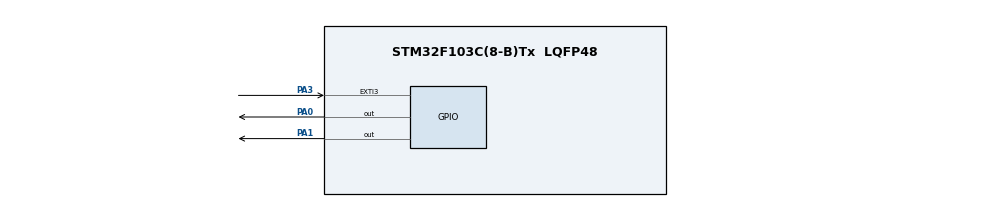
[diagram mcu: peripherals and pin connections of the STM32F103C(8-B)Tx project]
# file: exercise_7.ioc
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Mcu.Family=STM32F1
Mcu.Name=STM32F103C(8-B)Tx
Mcu.Package=LQFP48
NVIC.EXTI3_IRQn=true\:5\:0\:true\:false\:true\:true\:true\:true
NVIC.PriorityGroup=NVIC_PRIORITYGROUP_4
NVIC.TIM2_IRQn=true\:15\:0\:false\:false\:true\:false\:true\:true
NVIC.TimeBase=TIM2_IRQn
NVIC.TimeBaseIP=TIM2
PA0-WKUP.Signal=GPIO_Output
PA1.Signal=GPIO_Output
PA13.Mode=Serial_Wire
PA13.Signal=SYS_JTMS-SWDIO
PA14.Mode=Serial_Wire
PA14.Signal=SYS_JTCK-SWCLK
PA3.Signal=GPXTI3
ProjectManager.HeapSize=0x200
ProjectManager.StackSize=0x400
ProjectManager.TargetToolchain=STM32CubeIDE
RCC.APB1Freq_Value=8000000
RCC.APB2Freq_Value=8000000
VP_SYS_VS_tim2.Mode=TIM2
board=custom

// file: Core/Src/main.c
/* USER CODE BEGIN Header */
/**
  ******************************************************************************
  * @file           : main.c
  * @brief          : Main program body
  ******************************************************************************
  * @attention
  *
  * Copyright (c) 2024 STMicroelectronics.
  * All rights reserved.
  *
  * This software is licensed under terms that can be found in the LICENSE file
  * in the root directory of this software component.
  * If no LICENSE file comes with this software, it is provided AS-IS.
  *
  ******************************************************************************
  */
/* USER CODE END Header */
#include "main.h"

/* USER CODE BEGIN Includes */
#include "FreeRTOS.h"
#include "task.h"
/* USER CODE END Includes */

/* USER CODE BEGIN PV */
    TaskHandle_t Task_1_handle =NULL, Task_2_handle= NULL;
    int ButtonState = GPIO_PIN_RESET;
    int Task1,Task2;

    void switchPriority()
    {
    	int state=0;
    	TaskHandle_t t1,t2;

    	t1= xTaskGetHandle("Toggle_1");
    	t2= xTaskGetHandle("Toggle_2");

    	taskENTER_CRITICAL();
    	if(ButtonState == GPIO_PIN_SET)
    	{
    		ButtonState = GPIO_PIN_RESET;
    		state=1;
    	}
    	taskEXIT_CRITICAL();

    	if(state)
    	{
    		state=0;
    		vTaskPrioritySet( t1 , uxTaskPriorityGet(  t2 ));
    		vTaskPrioritySet( t2 , uxTaskPriorityGet(  t1 ));
    	}
    }

void Task_1_Handler(void * parameters)
{
	while(1)
	{
		HAL_GPIO_TogglePin(GPIOA, GPIO_PIN_0);
		Task1 ^=1;
		vTaskDelay(pdMS_TO_TICKS(100));
		switchPriority();
	}
}

void Task_2_Handler(void * parameters)
{
	while(1)
	{
		HAL_GPIO_TogglePin(GPIOA, GPIO_PIN_1);
		Task2 ^=1;
		HAL_Delay(500);
		switchPriority();
	}
}

void vApplicationIdleHook()
{
	__WFI();
}

/* USER CODE END PV */

void SystemClock_Config(void);
static void MX_GPIO_Init(void);

int main(void)
{

  /* MCU Configuration--------------------------------------------------------*/

  /* Reset of all peripherals, Initializes the Flash interface and the Systick. */
  HAL_Init();

  /* Configure the system clock */
  SystemClock_Config();

  /* Initialize all configured peripherals */
  MX_GPIO_Init();
  /* USER CODE BEGIN 2 */
  xTaskCreate( Task_1_Handler, "Toggle_1", 100, NULL, 2, &Task_1_handle );
  xTaskCreate( Task_2_Handler, "Toggle_2", 100, NULL, 3, &Task_2_handle );

  vTaskStartScheduler();
  /* USER CODE END 2 */

  /* Infinite loop */
  while (1)
  {

  }
}

void SystemClock_Config(void)
{
  RCC_OscInitTypeDef RCC_OscInitStruct = {0};
  RCC_ClkInitTypeDef RCC_ClkInitStruct = {0};

  /** Initializes the RCC Oscillators according to the specified parameters
  * in the RCC_OscInitTypeDef structure.
  */
  RCC_OscInitStruct.OscillatorType = RCC_OSCILLATORTYPE_HSI;
  RCC_OscInitStruct.HSIState = RCC_HSI_ON;
  RCC_OscInitStruct.HSICalibrationValue = RCC_HSICALIBRATION_DEFAULT;
  RCC_OscInitStruct.PLL.PLLState = RCC_PLL_NONE;
  if (HAL_RCC_OscConfig(&RCC_OscInitStruct) != HAL_OK)
  {
    Error_Handler();
  }

  /** Initializes the CPU, AHB and APB buses clocks
  */
  RCC_ClkInitStruct.ClockType = RCC_CLOCKTYPE_HCLK|RCC_CLOCKTYPE_SYSCLK
                              |RCC_CLOCKTYPE_PCLK1|RCC_CLOCKTYPE_PCLK2;
  RCC_ClkInitStruct.SYSCLKSource = RCC_SYSCLKSOURCE_HSI;
  RCC_ClkInitStruct.AHBCLKDivider = RCC_SYSCLK_DIV1;
  RCC_ClkInitStruct.APB1CLKDivider = RCC_HCLK_DIV1;
  RCC_ClkInitStruct.APB2CLKDivider = RCC_HCLK_DIV1;

  if (HAL_RCC_ClockConfig(&RCC_ClkInitStruct, FLASH_LATENCY_0) != HAL_OK)
  {
    Error_Handler();
  }
}

static void MX_GPIO_Init(void)
{
  GPIO_InitTypeDef GPIO_InitStruct = {0};

  /* GPIO Ports Clock Enable */
  __HAL_RCC_GPIOA_CLK_ENABLE();

  /*Configure GPIO pin Output Level */
  HAL_GPIO_WritePin(GPIOA, GPIO_PIN_0|GPIO_PIN_1, GPIO_PIN_RESET);

  /*Configure GPIO pins : PA0 PA1 */
  GPIO_InitStruct.Pin = GPIO_PIN_0|GPIO_PIN_1;
  GPIO_InitStruct.Mode = GPIO_MODE_OUTPUT_PP;
  GPIO_InitStruct.Pull = GPIO_NOPULL;
  GPIO_InitStruct.Speed = GPIO_SPEED_FREQ_LOW;
  HAL_GPIO_Init(GPIOA, &GPIO_InitStruct);

  /*Configure GPIO pin : PA3 */
  GPIO_InitStruct.Pin = GPIO_PIN_3;
  GPIO_InitStruct.Mode = GPIO_MODE_IT_RISING;
  GPIO_InitStruct.Pull = GPIO_NOPULL;
  HAL_GPIO_Init(GPIOA, &GPIO_InitStruct);

  /* EXTI interrupt init*/
  HAL_NVIC_SetPriority(EXTI3_IRQn, 5, 0);
  HAL_NVIC_EnableIRQ(EXTI3_IRQn);

}

void HAL_TIM_PeriodElapsedCallback(TIM_HandleTypeDef *htim)
{
  if (htim->Instance == TIM2) {
    HAL_IncTick();
  }
}

void Error_Handler(void)
{
  __disable_irq();
  while (1)
  {
  }
}
